# DECODER0_MSVDX_VEC_H264 register map
Vendor: Texas Instruments
Peripheral module from a debugger description file (folder J7ES).
Registers are 32-bit, read-write, reset 0x0 unless marked. A register's access mark holds for its fields unless they carry their own. Offsets are as the file gives them; lines under a group give offsets from that group; [hi:lo] are bit positions; {n}, {i} and the like mark numbered series; 'fields as' and 'values as' point back to an identical list; <NAME> marks a mode.

## DECODER0_MSVDX_VEC_H264
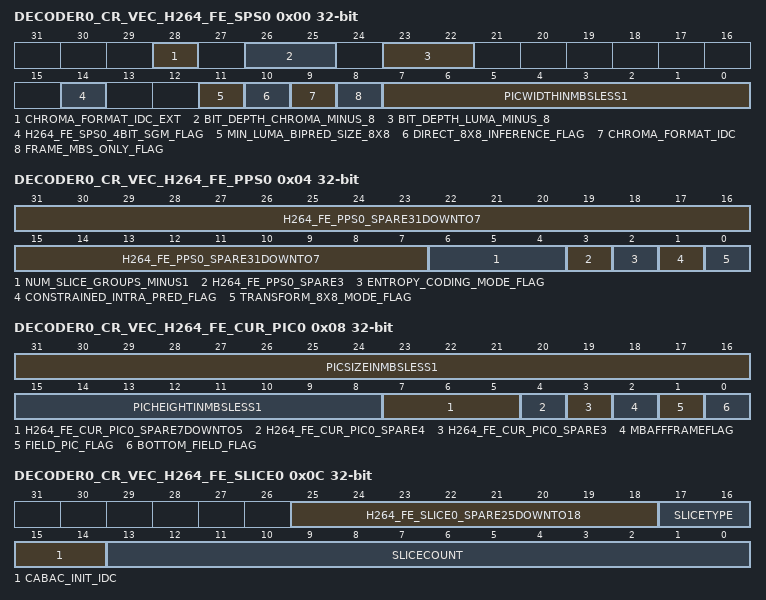
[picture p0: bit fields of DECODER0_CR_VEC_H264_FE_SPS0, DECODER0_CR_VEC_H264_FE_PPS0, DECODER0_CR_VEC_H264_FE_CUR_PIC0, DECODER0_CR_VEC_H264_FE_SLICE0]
0x00 DECODER0_CR_VEC_H264_FE_SPS0 — Front End H.264 sequence-level parameters (from a Sequence Parameter Set). This contains similar parameters to the register BE_SPS0
  [28] CHROMA_FORMAT_IDC_EXT — Sequence parameter set RBSP syntax - chroma_format_idc, for MSVDX Core &gt;= 6
  [26:25] BIT_DEPTH_CHROMA_MINUS_8 — Specifies the bit depth of the samples of the chroma arrays for Core Revisions &gt; 6.0.0
  [23:22] BIT_DEPTH_LUMA_MINUS_8 — Specifies the bit depth of the samples of the luma arrays for Core Revisions &gt; 6.0.0
  [14] H264_FE_SPS0_4BIT_SGM_FLAG — Indicates that the slice group map in VEC_H264_FE_BASE_ADDR_SGM is packed every 4 bits, rather than 8 bits
  [11] MIN_LUMA_BIPRED_SIZE_8X8 — When H.264 profile is 3.1 or greater, this bit shall be set to 1
  [10] DIRECT_8X8_INFERENCE_FLAG — Sequence parameter set RBSP syntax - direct_8x8_inference_flag
  [9] CHROMA_FORMAT_IDC — Sequence parameter set RBSP syntax - chroma_format_idc
  [8] FRAME_MBS_ONLY_FLAG — Sequence parameter set RBSP syntax - frame_mbs_only_flag
  [7:0] PICWIDTHINMBSLESS1 — Picture Width in [macroblocks - 1]
0x04 DECODER0_CR_VEC_H264_FE_PPS0 — Front End H.264 picture-level parameters (from a Picture Parameter Set). This contains similar parameters to the register BE_PPS0
  [31:7] H264_FE_PPS0_SPARE31DOWNTO7 — Reserved
  [6:4] NUM_SLICE_GROUPS_MINUS1 — Picture parameter set RBSP syntax - num_slice_groups_minus1
  [3] H264_FE_PPS0_SPARE3 — Reserved
  [2] ENTROPY_CODING_MODE_FLAG
  [1] CONSTRAINED_INTRA_PRED_FLAG — Picture parameter set RBSP syntax - constrained_intra_pred_flag
  [0] TRANSFORM_8X8_MODE_FLAG — Picture parameter set RBSP syntax - transform_8x8_mode_flag
0x08 DECODER0_CR_VEC_H264_FE_CUR_PIC0 — Front End H.264 picture-level parameters (from a Slice Header) describing the current picture. This contains similar parameters to the register BE_CUR_PIC0
  [31:16] PICSIZEINMBSLESS1 — Picture size in [macroblocks - 1]
  [15:8] PICHEIGHTINMBSLESS1 — Picture Height in [macroblocks - 1]
  [7:5] H264_FE_CUR_PIC0_SPARE7DOWNTO5 — Reserved
  [4] H264_FE_CUR_PIC0_SPARE4
  [3] H264_FE_CUR_PIC0_SPARE3 — Reserved
  [2] MBAFFFRAMEFLAG
  [1] FIELD_PIC_FLAG — Slice header syntax - field_pic_flag
  [0] BOTTOM_FIELD_FLAG — Slice header syntax - bottom_field_flag
0x0C DECODER0_CR_VEC_H264_FE_SLICE0 — Front End H.264 slice-level parameters (from a Slice Header). This contains similar parameters to the register BE_SLICE0
  [25:18] H264_FE_SLICE0_SPARE25DOWNTO18 — Reserved
  [17:16] SLICETYPE — MSVDX slice type:
  [15:14] CABAC_INIT_IDC — Slice header syntax - cabac_init_idc
  [13:0] SLICECOUNT
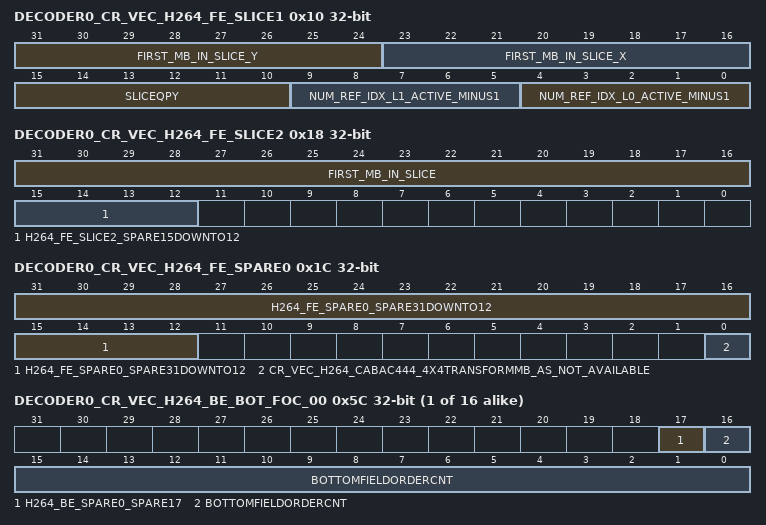
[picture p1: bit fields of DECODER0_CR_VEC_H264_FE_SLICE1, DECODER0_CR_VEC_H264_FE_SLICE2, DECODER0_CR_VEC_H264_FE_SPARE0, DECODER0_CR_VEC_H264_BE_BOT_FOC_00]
0x10 DECODER0_CR_VEC_H264_FE_SLICE1 — Front End H.264 slice-level parameters (from a Slice Header). This contains similar parameters to the register BE_SLICE1
  [31:24] FIRST_MB_IN_SLICE_Y — The macroblock address of the first macroblock in the slice in Y axis
  [23:16] FIRST_MB_IN_SLICE_X — The macroblock address of the first macroblock in the slice in X axis
  [15:10] SLICEQPY
  [9:5] NUM_REF_IDX_L1_ACTIVE_MINUS1 — Slice header syntax - num_ref_idx_l1_active_minus1
  [4:0] NUM_REF_IDX_L0_ACTIVE_MINUS1 — Slice header syntax - num_ref_idx_l0_active_minus1
0x14 DECODER0_CR_VEC_H264_FE_BASE_ADDR_SGM — Front End H.264 base address for the 'map unit to slice group map' for the current picture. This base address will only be valid if the value of 'num_slice_groups_minus1' in the register FE_PPS0 is greater than 0
  [31:12] MAPUNITTOSLICEGROUPMAP — mapUnitToSliceGroupMap data structure base address
0x18 DECODER0_CR_VEC_H264_FE_SLICE2
  [31:16] FIRST_MB_IN_SLICE — Slice header syntax - first_mb_in_slice
  [15:12] H264_FE_SLICE2_SPARE15DOWNTO12 — Spare bits for other codec registers
0x1C DECODER0_CR_VEC_H264_FE_SPARE0
  [31:12] H264_FE_SPARE0_SPARE31DOWNTO12 — Reserved
  [0] CR_VEC_H264_CABAC444_4X4TRANSFORMMB_AS_NOT_AVAILABLE — Activate specific logic to cope with x264 divergence from the h.264 specification:
0x20 DECODER0_CR_VEC_H264_FE_SPARE1
  [31:0] H264_FE_SPARE1_SPARE31DOWNTO0 — Reserved
0x24 DECODER0_CR_VEC_H264_FE_SPARE2
  [31:0] H264_FE_SPARE2_SPARE31DOWNTO0
0x2C DECODER0_CR_VEC_H264_ERROR_DETECTION — Enable/disable different points in Entropy parse to detect potential errors during decode. Some of these error detection procedures may cause different issues with some no fully compliant streams.
  [0] CR_VEC_H264_IMPLICIT_EOS — Enable/disable error detection when the last slice overrun the picture size.
{0x30+4i} DECODER0_CR_VEC_H264_FE_SPARE_N_{i:02} (i=0..7)
  [27:0] H264_FE_SPARE27DOWNTO0 — Spare bits
0x50 DECODER0_CR_VEC_H264_BE_FOC0 — Back End H.264 Top Field Order Count for the current picture
  [16:0] TOPFIELDORDERCNT_CURR — Top field order count for current picture
0x54 DECODER0_CR_VEC_H264_BE_FOC1 — Back End H.264 Bottom Field Order Count for the current picture
  [16:0] BOTTOMFIELDORDERCNT_CURR — Bottom field order count for current picture
{0x58+8i} DECODER0_CR_VEC_H264_BE_TOP_FOC_{i:02} (i=0..15) — Top field picture order counts (POC) for pictures in Decoded Picture Buffer
  [16:0] TOPFIELDORDERCNT — Top field order count for each picture in the DPB
{0x5C+8i} DECODER0_CR_VEC_H264_BE_BOT_FOC_{i:02} (i=0..15) — Bottom field picture order counts (POC) for pictures in the decoded picture buffer (DPB)
  [17] H264_BE_SPARE0_SPARE17 — Spare bit for use in other codec registers
  [16:0] BOTTOMFIELDORDERCNT — Bottom field order count for each picture in the DPB
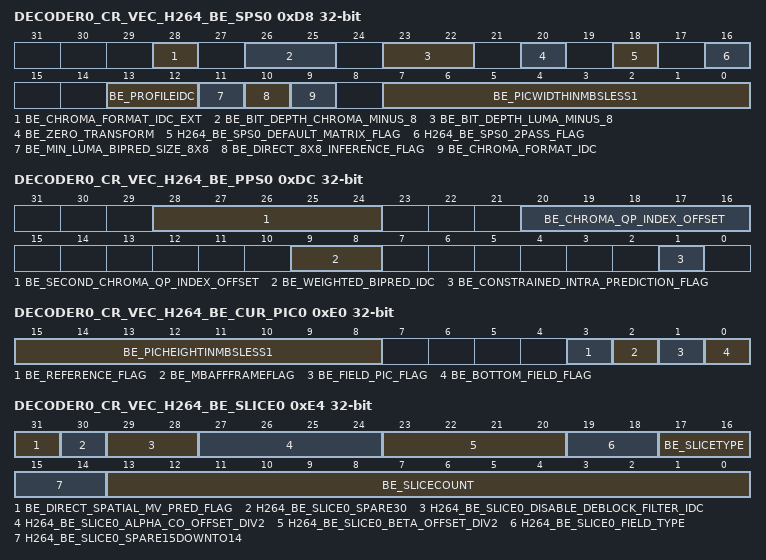
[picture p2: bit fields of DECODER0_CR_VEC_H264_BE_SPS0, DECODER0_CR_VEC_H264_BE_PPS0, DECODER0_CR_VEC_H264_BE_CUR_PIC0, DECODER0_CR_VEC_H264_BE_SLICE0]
0xD8 DECODER0_CR_VEC_H264_BE_SPS0 — Back End H.264 sequence-level parameters (from a Sequence Parameter Set) stored after passing through Rendec. This register contains similar parameters to the register FE_SPS0
  [28] BE_CHROMA_FORMAT_IDC_EXT — Sequence parameter set RBSP syntax - chroma_format_idc, for MSVDX Core &gt;= 6
  [26:25] BE_BIT_DEPTH_CHROMA_MINUS_8 — Specifies the bit depth of the samples of the chroma arrays for Core Revisions &gt; 6.0.0
  [23:22] BE_BIT_DEPTH_LUMA_MINUS_8 — Specifies the bit depth of the samples of the luma arrays for Core Revisions &gt; 6.0.0
  [20] BE_ZERO_TRANSFORM — Indicates the stream supports Lossless Macroblocks.
  [18] H264_BE_SPS0_DEFAULT_MATRIX_FLAG — Indicates that IQ should use it's default scaling matricies
  [16] H264_BE_SPS0_2PASS_FLAG — Indicates that the current sequence may contain non-consecutive MBs
  [13:12] BE_PROFILEIDC — ProfileIdc [for IQ]:
  [11] BE_MIN_LUMA_BIPRED_SIZE_8X8 — When H.264 profile is 3.1 or greater, this bit shall be set to 1
  [10] BE_DIRECT_8X8_INFERENCE_FLAG — Direct 8x8 inference flag
  [9] BE_CHROMA_FORMAT_IDC — Sequence parameter set RBSP syntax - chroma_format_idc
  [7:0] BE_PICWIDTHINMBSLESS1 — Picture width in [macroblocks - 1]
0xDC DECODER0_CR_VEC_H264_BE_PPS0 — Back End H.264 picture-level parameters (from a Picture Parameter Set) stored after passing through Rendec. This register contains similar parameters to the register FE_PPS0
  [28:24] BE_SECOND_CHROMA_QP_INDEX_OFFSET — Second_chroma_qp_index_offset
  [20:16] BE_CHROMA_QP_INDEX_OFFSET — Chroma Qp index offset
  [9:8] BE_WEIGHTED_BIPRED_IDC — Weighted_bipred_idc for the current picture
  [1] BE_CONSTRAINED_INTRA_PREDICTION_FLAG — Constrained intra prediction flag for the current picture
0xE0 DECODER0_CR_VEC_H264_BE_CUR_PIC0 — Back End H.264 picture-level parameters (from a Slice Header) describing the current picture, stored after passing through Rendec. This contains similar parameters to the register FE_CUR_PIC0
  [15:8] BE_PICHEIGHTINMBSLESS1 — Picture height in [macroblocks - 1]
  [3] BE_REFERENCE_FLAG — Reference flag for the current picture
  [2] BE_MBAFFFRAMEFLAG — MbaffFrameFlag
  [1] BE_FIELD_PIC_FLAG — Field pic flag for the current picture
  [0] BE_BOTTOM_FIELD_FLAG — Bottom field flag for the current picture
0xE4 DECODER0_CR_VEC_H264_BE_SLICE0 — Back End H.264 slice-level parameters (from Slice Header) stored after passing through Rendec. This register contains similar parameters to the register FE_SLICE0
  [31] BE_DIRECT_SPATIAL_MV_PRED_FLAG — Direct_spatial_mv_pred_flag for the current picture
  [30] H264_BE_SLICE0_SPARE30 — Reserved
  [29:28] H264_BE_SLICE0_DISABLE_DEBLOCK_FILTER_IDC
  [27:24] H264_BE_SLICE0_ALPHA_CO_OFFSET_DIV2 — Specifies the offset used in accessing the alpha and tco deblocking filter tables for filtering operations controlled by the macroblocks within the slice.
  [23:20] H264_BE_SLICE0_BETA_OFFSET_DIV2 — Specifies the offset used in accessing the beta deblocking filter tables for filtering operations controlled by the macroblocks within the slice.
  [19:18] H264_BE_SLICE0_FIELD_TYPE — SLICE_FIELD_TYPE of the Operating Mode Command
  [17:16] BE_SLICETYPE — MSVDX slice type:
  [15:14] H264_BE_SLICE0_SPARE15DOWNTO14 — Reserved
  [13:0] BE_SLICECOUNT — SliceCount - increments from 0 for each slice in currPic
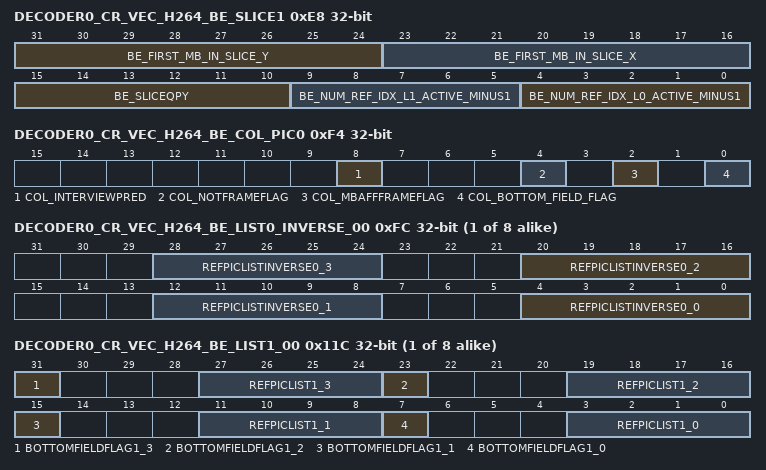
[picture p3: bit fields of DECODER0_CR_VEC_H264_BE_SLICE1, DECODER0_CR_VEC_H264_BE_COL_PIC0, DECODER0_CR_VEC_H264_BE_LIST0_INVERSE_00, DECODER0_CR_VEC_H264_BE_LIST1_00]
0xE8 DECODER0_CR_VEC_H264_BE_SLICE1 — Back End H.264 slice-level parameters (from Slice Header) stored after passing through Rendec. This contains similar parameters to the register FE_SLICE1
  [31:24] BE_FIRST_MB_IN_SLICE_Y — The macroblock address of the first macroblock in the slice in Y coordinate
  [23:16] BE_FIRST_MB_IN_SLICE_X — The macroblock address of the first macroblock in the slice in X coordinate
  [15:10] BE_SLICEQPY — Slice QPY for the current picture
  [9:5] BE_NUM_REF_IDX_L1_ACTIVE_MINUS1 — num_ref_idx_l1_active_minus1
  [4:0] BE_NUM_REF_IDX_L0_ACTIVE_MINUS1 — num_ref_idx_l0_active_minus1
0xEC DECODER0_CR_VEC_H264_BE_BASE_ADDR_CUR_PIC — Back End H.264 base address for the macroblock parameters to be stored for the current picture
  [31:12] CURRPIC_PARAMS_BASE_ADDRESS — currPic parameters base address
0xF0 DECODER0_CR_VEC_H264_BE_REF0 — Back End H.264 long term reference picture status flags for each picture in the Decoded Picture Buffer. Stored after passing through Rendec
  [15:0] BE_LONGTERMFRAMEFLAG — Long term frame flag for each reference frame in the Decoded Picture Buffer
0xF4 DECODER0_CR_VEC_H264_BE_COL_PIC0 — Back End H.264 colocated picture parameters. This register contains similar parameters to the registers FE_CUR_PIC0 and BE_CUR_PIC0. However, the parameters for the colocated picture can change per slice
  [8] COL_INTERVIEWPRED — Should be set when RefPicList1{0} is an inter view prediction reference.
  [4] COL_NOTFRAMEFLAG — Flag set if colocated picture is a field pair not a frame
  [2] COL_MBAFFFRAMEFLAG — Mbaff frame flag for colocated picture
  [0] COL_BOTTOM_FIELD_FLAG — When VEC_H264_BE_CUR_PIC0 BE_FIELD_PIC_FLAG =
0xF8 DECODER0_CR_VEC_H264_BE_BASE_ADDR_COL_PIC — Back End H.264 base address to read the macroblock parameters for the colocated picture. This address can change per slice
  [31:12] COL_PIC_PARAMS_BASE_ADDRESS — Parameters base address for colocated picture
{0xFC+4i} DECODER0_CR_VEC_H264_BE_LIST0_INVERSE_{i:02} (i=0..7) — Reference picture list 0 inverse maps dpbIdx and bottom field flag to refIdx. This is used to determine refIdx_l0 in B temporal direct prediction. In frame mode, only the first 16 entries are used (ignoring bottom field flag). In field mode, the first 16 entires cover top fields and the second 16 entries cover bottom fields
  [8n+4:8n] REFPICLISTINVERSE0_{n} (n=0..3) — Lowest index in refPicList0 of the picture stored in the given DPB slot
{0x11C+4i} DECODER0_CR_VEC_H264_BE_LIST1_{i:02} (i=0..7) — Reference picture list 1, maps reference index to DPB index (including top/bottom field in interlaced mode). Can change per-slice
  [31] BOTTOMFIELDFLAG1_3 — Bottom field flag indicating that this reference refers to the bottom field of the picture in the associated DPB slot
  [27:24] REFPICLIST1_3 — DPB index of the reference picture
  [23] BOTTOMFIELDFLAG1_2 — Bottom field flag indicating that this reference refers to the bottom field of the picture in the associated DPB slot
  [19:16] REFPICLIST1_2 — DPB index of the reference picture
  [15] BOTTOMFIELDFLAG1_1 — Bottom field flag indicating that this reference refers to the bottom field of the picture in the associated DPB slot
  [11:8] REFPICLIST1_1 — DPB index of the reference picture
  [7] BOTTOMFIELDFLAG1_0 — Bottom field flag indicating that the reference refers to the bottom field stored in the associated DPB slot
  [3:0] REFPICLIST1_0 — DPB index of reference picture
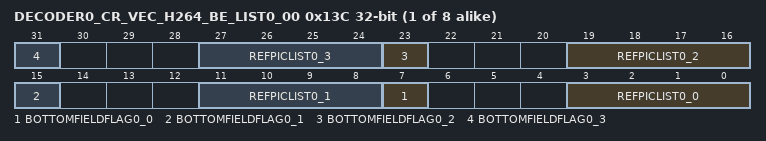
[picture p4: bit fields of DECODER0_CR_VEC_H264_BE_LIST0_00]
{0x13C+4i} DECODER0_CR_VEC_H264_BE_LIST0_{i:02} (i=0..7) — Reference picture list 0, maps reference index to Decoded Picture Buffer (DPB) index (including top/bottom field in interlaced mode). Can change per-slice
  [8n+7] BOTTOMFIELDFLAG0_{n} (n=0..3) — Bottom field flag indicating that this reference refers to the bottom field of the picture in the associated DPB slot
  [8n+3:8n] REFPICLIST0_{n} (n=0..3) — DPB index of the reference picture
0x15C DECODER0_CR_VEC_H264_BE_INTRA_8X8 — Disable filter for X264 encoded lossless streams as needed.
  [0] CR_VEC_H264_BE_INTRA_8X8_DISABLE_FILTER_FLAG — Disable the VDMC filter for 8x8 blocks on X264 encoded lossless streams.
